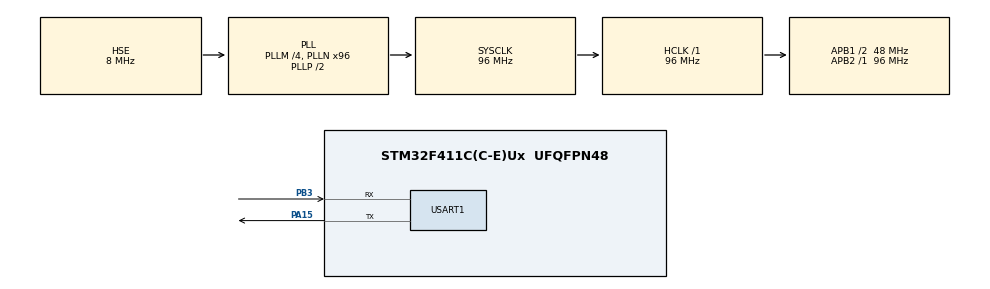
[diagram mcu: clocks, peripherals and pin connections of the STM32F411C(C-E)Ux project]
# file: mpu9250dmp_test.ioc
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Mcu.Family=STM32F4
Mcu.Name=STM32F411C(C-E)Ux
Mcu.Package=UFQFPN48
NVIC.PriorityGroup=NVIC_PRIORITYGROUP_4
PA13.Mode=Serial_Wire
PA13.Signal=SYS_JTMS-SWDIO
PA14.Mode=Serial_Wire
PA14.Signal=SYS_JTCK-SWCLK
PA15.Mode=Asynchronous
PA15.Signal=USART1_TX
PB3.Mode=Asynchronous
PB3.Signal=USART1_RX
PH0\ -\ OSC_IN.Mode=HSE-External-Oscillator
PH0\ -\ OSC_IN.Signal=RCC_OSC_IN
PH1\ -\ OSC_OUT.Mode=HSE-External-Oscillator
PH1\ -\ OSC_OUT.Signal=RCC_OSC_OUT
ProjectManager.HeapSize=0x200
ProjectManager.StackSize=0x400
ProjectManager.TargetToolchain=MDK-ARM V5.27
RCC.48MHZClocksFreq_Value=48000000
RCC.AHBFreq_Value=96000000
RCC.APB1CLKDivider=RCC_HCLK_DIV2
RCC.APB1Freq_Value=48000000
RCC.APB1TimFreq_Value=96000000
RCC.APB2Freq_Value=96000000
RCC.APB2TimFreq_Value=96000000
RCC.CortexFreq_Value=96000000
RCC.HCLKFreq_Value=96000000
RCC.HSE_VALUE=8000000
RCC.HSI_VALUE=16000000
RCC.LSE_VALUE=32768
RCC.PLLM=4
RCC.PLLN=96
RCC.PLLSourceVirtual=RCC_PLLSOURCE_HSE
RCC.SYSCLKFreq_VALUE=96000000
RCC.SYSCLKSource=RCC_SYSCLKSOURCE_PLLCLK
RCC.VCOOutputFreq_Value=192000000
USART1.VirtualMode=VM_ASYNC
board=custom

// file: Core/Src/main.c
/* USER CODE BEGIN Header */
/**
  ******************************************************************************
  * @file           : main.c
  * @brief          : Main program body
  ******************************************************************************
  * @attention
  *
  * Copyright (c) 2023 STMicroelectronics.
  * All rights reserved.
  *
  * This software is licensed under terms that can be found in the LICENSE file
  * in the root directory of this software component.
  * If no LICENSE file comes with this software, it is provided AS-IS.
  *
  ******************************************************************************
  */
/* USER CODE END Header */
#include "main.h"
#include "usart.h"
#include "gpio.h"

/* USER CODE BEGIN Includes */
#include "sys.h"
#include "delay.h"
#include "myiic.h"
#include "mpu9250.h"
#include "inv_mpu.h"
#include "inv_mpu_dmp_motion_driver.h"

/* USER CODE END Includes */

void SystemClock_Config(void);
/* USER CODE BEGIN PFP */
//串口1发送1个字符
//c:要发送的字符
void usart1_send_char(u8 c)
{
    while(__HAL_UART_GET_FLAG(&huart1,UART_FLAG_TC)==RESET){};
    USART1->DR=c;
}

//传送数据给匿名四轴上位机软件(V2.6版本)
//fun:功能字. 0X01~0X1C
//data:数据缓存区,最多28字节!!
//len:data区有效数据个数
void usart1_niming_report(u8 fun,u8*data,u8 len)
{
	u8 send_buf[32];
	u8 i;
	if(len>28)return;	//最多28字节数据
	send_buf[len+4]=0;	//校验数置零
	send_buf[0]=0XAA;	//帧头
	send_buf[1]=0XAA;	//帧头
	send_buf[2]=fun;	//功能字
	send_buf[3]=len;	//数据长度
	for(i=0;i<len;i++)send_buf[4+i]=data[i];			//复制数据
	for(i=0;i<len+4;i++)send_buf[len+4]+=send_buf[i];	//计算校验和
	for(i=0;i<len+5;i++)usart1_send_char(send_buf[i]);	//发送数据到串口1
}
//发送加速度传感器数据+陀螺仪数据(传感器帧)
//aacx,aacy,aacz:x,y,z三个方向上面的加速度值
//gyrox,gyroy,gyroz:x,y,z三个方向上面的陀螺仪值
void mpu6050_send_data(short aacx,short aacy,short aacz,short gyrox,short gyroy,short gyroz)
{
	u8 tbuf[18];
	tbuf[0]=(aacx>>8)&0XFF;
	tbuf[1]=aacx&0XFF;
	tbuf[2]=(aacy>>8)&0XFF;
	tbuf[3]=aacy&0XFF;
	tbuf[4]=(aacz>>8)&0XFF;
	tbuf[5]=aacz&0XFF;
	tbuf[6]=(gyrox>>8)&0XFF;
	tbuf[7]=gyrox&0XFF;
	tbuf[8]=(gyroy>>8)&0XFF;
	tbuf[9]=gyroy&0XFF;
	tbuf[10]=(gyroz>>8)&0XFF;
	tbuf[11]=gyroz&0XFF;
	tbuf[12]=0;//因为开启MPL后,无法直接读取磁力计数据,所以这里直接屏蔽掉.用0替代.
	tbuf[13]=0;
	tbuf[14]=0;
	tbuf[15]=0;
	tbuf[16]=0;
	tbuf[17]=0;
	usart1_niming_report(0X02,tbuf,18);//传感器帧,0X02
}
//通过串口1上报结算后的姿态数据给电脑(状态帧)
//roll:横滚角.单位0.01度。 -18000 -> 18000 对应 -180.00  ->  180.00度
//pitch:俯仰角.单位 0.01度。-9000 - 9000 对应 -90.00 -> 90.00 度
//yaw:航向角.单位为0.1度 0 -> 3600  对应 0 -> 360.0度
//prs:气压计高度,单位:cm
//fly_mode:飞行模式
//armed:锁定状态
void usart1_report_imu(short roll,short pitch,short yaw,int prs, u8 fly_mode, u8 armed)
{
	u8 tbuf[12];
	tbuf[0]=(roll>>8)&0XFF;
	tbuf[1]=roll&0XFF;
	tbuf[2]=(pitch>>8)&0XFF;
	tbuf[3]=pitch&0XFF;
	tbuf[4]=(yaw>>8)&0XFF;
	tbuf[5]=yaw&0XFF;
	tbuf[6]=(prs>>24)&0XFF;
	tbuf[7]=(prs>>16)&0XFF;
	tbuf[8]=(prs>>8)&0XFF;
	tbuf[9]=prs&0XFF;
	tbuf[10]=fly_mode;
	tbuf[11]=armed;
	usart1_niming_report(0X01,tbuf,12);//状态帧,0X01
}

/* USER CODE END PFP */

int main(void)
{

  /* MCU Configuration--------------------------------------------------------*/

  /* Reset of all peripherals, Initializes the Flash interface and the Systick. */
  HAL_Init();

  /* Configure the system clock */
  SystemClock_Config();

  /* Initialize all configured peripherals */
  MX_GPIO_Init();
  MX_USART1_UART_Init();
  /* USER CODE BEGIN 2 */
	delay_init(96);  // 初始化时钟
	IIC_Init();
	u8 device_id;
	//(MPU9250_ADDR, MPU_DEVICE_ID_REG)
	u8 res;
	//printf("单片机正常运行\r\n");
	res = MPU_Read_Len(MPU9250_ADDR, MPU_DEVICE_ID_REG, 1, &device_id);
	//printf("the read is %d\r\n", res);
	if(res) {
		//printf("err\r\n");
		while(1);
	} else {
		//printf("OK\r\n");
	}
	//printf("the id is %#x\r\n", device_id);
	if(device_id == MPU6500_ID) {
		//printf("设备id检查正确\r\n");
	} else {
		//printf("请查看地址是否配置正确或者接线是否正确\r\n");
		while(1);
	}
	u8 err = mpu_dmp_init();
	if(err) {
		//printf("the err is %d\r\n", err);
		res = MPU_Read_Len(MPU9250_ADDR, MPU_DEVICE_ID_REG, 1, &device_id);
		//printf("the read is %d\r\n", res);
		//printf("the id is %#x\r\n", device_id);
		while(1);
	} else {
		//printf("mpu9250 init ok\r\n");
	}
	   float pitch,roll,yaw; 	        //欧拉角
    short aacx,aacy,aacz;	        //加速度传感器原始数据
    short gyrox,gyroy,gyroz;        //陀螺仪原始数据
    short temp;                     //温度
		u8 report = 1;
	  while(1)
    {
        err = mpu_mpl_get_data(&pitch,&roll,&yaw);
        if(err == 0)
        {
            temp = MPU_Get_Temperature();	                                     //得到温度值（扩大了100倍）
            MPU_Get_Accelerometer(&aacx,&aacy,&aacz);	                         //得到加速度传感器数据
            MPU_Get_Gyroscope(&gyrox,&gyroy,&gyroz);	                         //得到陀螺仪数据
            //mpu6050_send_data(aacx,aacy,aacz,gyrox,gyroy,gyroz);               //发送加速度+陀螺仪原始数据
//            printf("ok\r\n");
//            printf("roll = %f   pitch = %f   yaw = %f (T = %d)\r\n",roll,pitch,yaw,temp);
  			if(report)mpu6050_send_data(aacx,aacy,aacz,gyrox,gyroy,gyroz);//发送加速度+陀螺仪原始数据
			if(report)usart1_report_imu((int)(roll*100),(int)(pitch*100),(int)(yaw*100),0,0,0);

        }
    }

  /* USER CODE END 2 */

  /* Infinite loop */

  while (1)
  {
		printf("hello world\r\n");
		//HAL_Delay(1000);
		delay_ms(1000);
  }
}

void SystemClock_Config(void)
{
  RCC_OscInitTypeDef RCC_OscInitStruct = {0};
  RCC_ClkInitTypeDef RCC_ClkInitStruct = {0};

  /** Configure the main internal regulator output voltage
  */
  __HAL_RCC_PWR_CLK_ENABLE();
  __HAL_PWR_VOLTAGESCALING_CONFIG(PWR_REGULATOR_VOLTAGE_SCALE1);

  /** Initializes the RCC Oscillators according to the specified parameters
  * in the RCC_OscInitTypeDef structure.
  */
  RCC_OscInitStruct.OscillatorType = RCC_OSCILLATORTYPE_HSE;
  RCC_OscInitStruct.HSEState = RCC_HSE_ON;
  RCC_OscInitStruct.PLL.PLLState = RCC_PLL_ON;
  RCC_OscInitStruct.PLL.PLLSource = RCC_PLLSOURCE_HSE;
  RCC_OscInitStruct.PLL.PLLM = 4;
  RCC_OscInitStruct.PLL.PLLN = 96;
  RCC_OscInitStruct.PLL.PLLP = RCC_PLLP_DIV2;
  RCC_OscInitStruct.PLL.PLLQ = 4;
  if (HAL_RCC_OscConfig(&RCC_OscInitStruct) != HAL_OK)
  {
    Error_Handler();
  }

  /** Initializes the CPU, AHB and APB buses clocks
  */
  RCC_ClkInitStruct.ClockType = RCC_CLOCKTYPE_HCLK|RCC_CLOCKTYPE_SYSCLK
                              |RCC_CLOCKTYPE_PCLK1|RCC_CLOCKTYPE_PCLK2;
  RCC_ClkInitStruct.SYSCLKSource = RCC_SYSCLKSOURCE_PLLCLK;
  RCC_ClkInitStruct.AHBCLKDivider = RCC_SYSCLK_DIV1;
  RCC_ClkInitStruct.APB1CLKDivider = RCC_HCLK_DIV2;
  RCC_ClkInitStruct.APB2CLKDivider = RCC_HCLK_DIV1;

  if (HAL_RCC_ClockConfig(&RCC_ClkInitStruct, FLASH_LATENCY_3) != HAL_OK)
  {
    Error_Handler();
  }
}

void Error_Handler(void)
{
  __disable_irq();
  while (1)
  {
  }
}
